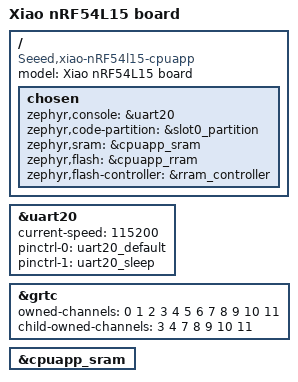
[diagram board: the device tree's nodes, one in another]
/dts-v1/;
#include <nordic/nrf54l15_cpuapp.dtsi>
#include "xiao_nRF54l15-pinctrl.dtsi"

/ {
	model = "Xiao nRF54L15 board";
	compatible = "Seeed,xiao-nRF54l15-cpuapp";

	chosen {
		zephyr,console = &uart20;
		zephyr,code-partition = &slot0_partition;
		zephyr,sram = &cpuapp_sram;
		zephyr,flash = &cpuapp_rram;
		zephyr,flash-controller = &rram_controller;
	};
};

&uart20 {
	status = "okay";
	current-speed = <115200>;
	pinctrl-0 = <&uart20_default>;
	pinctrl-1 = <&uart20_sleep>;
	pinctrl-names = "default", "sleep";
};

&grtc {
	owned-channels = <0 1 2 3 4 5 6 7 8 9 10 11>;
	/* Channels 7-11 reserved for Zero Latency IRQs, 3-4 for FLPR */
	child-owned-channels = <3 4 7 8 9 10 11>;
	status = "okay";
};

&cpuapp_sram {
	status = "okay";
};

#include <nordic/nrf54l15_partition.dtsi>
